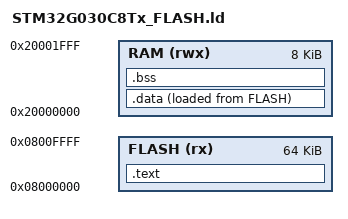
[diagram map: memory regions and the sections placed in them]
ENTRY(Reset_Handler)

MEMORY
{
    FLASH (rx) : ORIGIN = 0x08000000, LENGTH = 64K
    RAM (rwx)  : ORIGIN = 0x20000000, LENGTH = 8K
}

/* Top of stack at the end of RAM. */
__stack_bottom = ORIGIN(RAM) + LENGTH(RAM);

SECTIONS
{
    .text :
    {
        KEEP(*(.isr_vector))
        *(.text*)
        *(.rodata*)
        _etext = .;
    } > FLASH

    _sidata = LOADADDR(.data);
    .data :
    {
        _sdata = .;
        *(.data*)
        _edata = .;
    } > RAM AT > FLASH

    .bss :
    {
        _sbss = .;
        *(.bss*)
        *(COMMON)
        _ebss = .;
    } > RAM

    __bss_end__ = _ebss;
}
